# RZV2L register map
Vendor: Renesas; Series: All Chips; File version: x.xx
Registers are 32-bit, access not given, no defined reset value unless marked. A register's access mark holds for its fields unless they carry their own. Offsets are from the block's base; [hi:lo] are bit positions; {n}, {i} and the like mark numbered series.

## GPIO
Base 0x41030010
0x00 P10 8-bit
  [1:0] P10
0x01 P11 8-bit
  [1:0] P11
0x02 P12 8-bit
  [1:0] P12
0x03 P13 8-bit
  [1:0] P13
0x04 P14 8-bit
  [1:0] P14
0x05 P15 8-bit
  [2:0] P15
0x06 P16 8-bit
  [1:0] P16
0x07 P17 8-bit
  [2:0] P17
0x08 P18 8-bit
  [2:0] P18
0x09 P19 8-bit
  [1:0] P19
0x0A P1A 8-bit
  [1:0] P1A
0x0B P1B 8-bit
  [1:0] P1B
0x0C P1C 8-bit
  [1:0] P1C
0x0D P1D 8-bit
  [2:0] P1D
0x0E P1E 8-bit
  [1:0] P1E
0x0F P1F 8-bit
  [1:0] P1F
0x10 P20 8-bit
  [1:0] P20
0x11 P21 8-bit
  [2:0] P21
0x12 P22 8-bit
  [1:0] P22
0x13 P23 8-bit
  [1:0] P23
0x14 P24 8-bit
  [2:0] P24
0x15 P25 8-bit
  [1:0] P25
0x16 P26 8-bit
  [1:0] P26
0x17 P27 8-bit
  [1:0] P27
0x18 P28 8-bit
  [1:0] P28
0x19 P29 8-bit
  [1:0] P29
0x1A P2A 8-bit
  [1:0] P2A
0x1B P2B 8-bit
  [1:0] P2B
0x1C P2C 8-bit
  [1:0] P2C
0x1D P2D 8-bit
  [1:0] P2D
0x1E P2E 8-bit
  [1:0] P2E
0x1F P2F 8-bit
  [1:0] P2F
{0x2+i} P{i} 8-bit (i=30..34)
  [1:0] P{i}
0x25 P35 8-bit
  [2:0] P35
0x26 P36 8-bit
  [1:0] P36
0x27 P37 8-bit
  [2:0] P37
0x28 P38 8-bit
  [2:0] P38
0x29 P39 8-bit
  [1:0] P39
0x2A P3A 8-bit
  [4:0] P3A
0x2B P3B 8-bit
  [3:0] P3B
0x2C P3C 8-bit
  [3:0] P3C
0x2D P3D 8-bit
  [3:0] P3D
0x2E P3E 8-bit
  [3:0] P3E
0x2F P3F 8-bit
  [3:0] P3F
0x30 P40 8-bit
  [4:0] P40
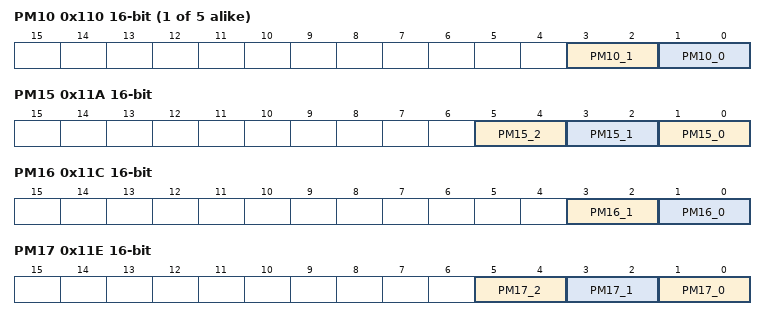
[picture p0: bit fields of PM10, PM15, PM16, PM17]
{0xFC+2i} PM{i} 16-bit (i=10..14)
  [3:2] PM{i}_1, [1:0] PM{i}_0
0x11A PM15 16-bit
  [5:4] PM15_2, [3:2] PM15_1, [1:0] PM15_0
0x11C PM16 16-bit
  [3:2] PM16_1, [1:0] PM16_0
0x11E PM17 16-bit
  [5:4] PM17_2, [3:2] PM17_1, [1:0] PM17_0
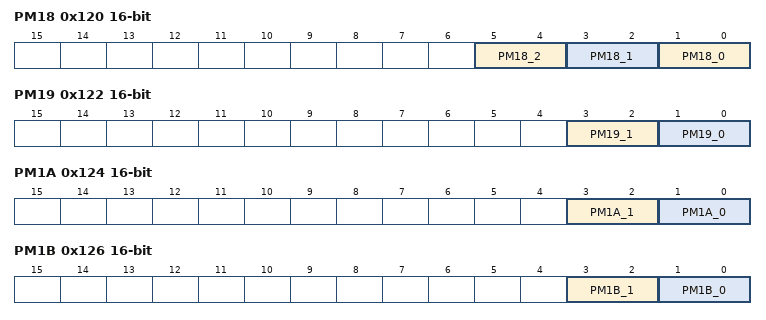
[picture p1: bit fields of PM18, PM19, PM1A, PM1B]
0x120 PM18 16-bit
  [5:4] PM18_2, [3:2] PM18_1, [1:0] PM18_0
0x122 PM19 16-bit
  [3:2] PM19_1, [1:0] PM19_0
0x124 PM1A 16-bit
  [3:2] PM1A_1, [1:0] PM1A_0
0x126 PM1B 16-bit
  [3:2] PM1B_1, [1:0] PM1B_0
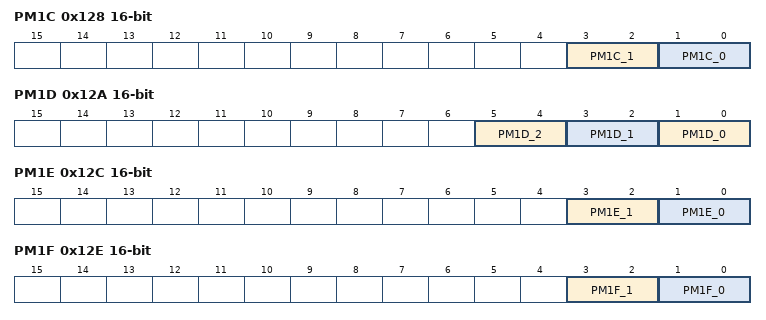
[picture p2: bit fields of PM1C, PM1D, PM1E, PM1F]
0x128 PM1C 16-bit
  [3:2] PM1C_1, [1:0] PM1C_0
0x12A PM1D 16-bit
  [5:4] PM1D_2, [3:2] PM1D_1, [1:0] PM1D_0
0x12C PM1E 16-bit
  [3:2] PM1E_1, [1:0] PM1E_0
0x12E PM1F 16-bit
  [3:2] PM1F_1, [1:0] PM1F_0
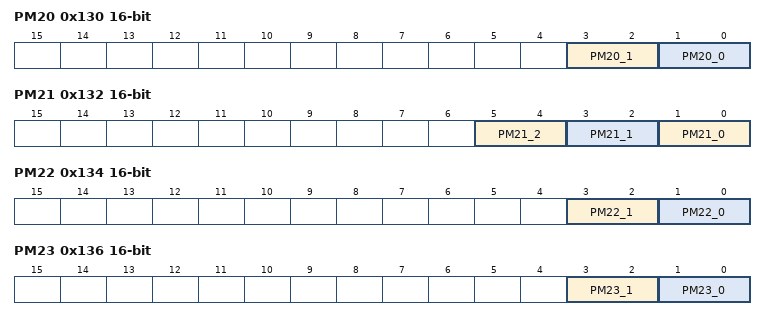
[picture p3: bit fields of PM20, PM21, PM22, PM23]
0x130 PM20 16-bit
  [3:2] PM20_1, [1:0] PM20_0
0x132 PM21 16-bit
  [5:4] PM21_2, [3:2] PM21_1, [1:0] PM21_0
0x134 PM22 16-bit
  [3:2] PM22_1, [1:0] PM22_0
0x136 PM23 16-bit
  [3:2] PM23_1, [1:0] PM23_0
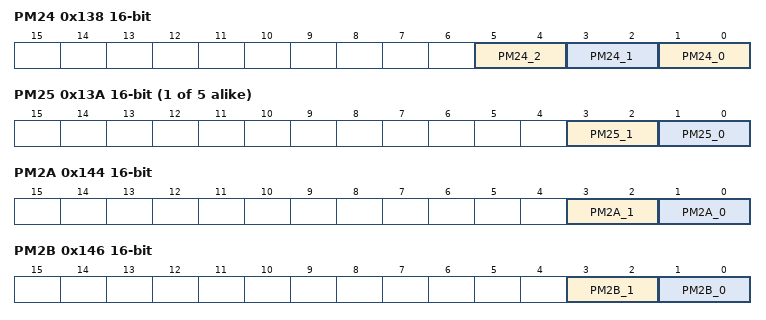
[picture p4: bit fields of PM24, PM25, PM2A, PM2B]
0x138 PM24 16-bit
  [5:4] PM24_2, [3:2] PM24_1, [1:0] PM24_0
{0x108+2i} PM{i} 16-bit (i=25..29)
  [3:2] PM{i}_1, [1:0] PM{i}_0
0x144 PM2A 16-bit
  [3:2] PM2A_1, [1:0] PM2A_0
0x146 PM2B 16-bit
  [3:2] PM2B_1, [1:0] PM2B_0
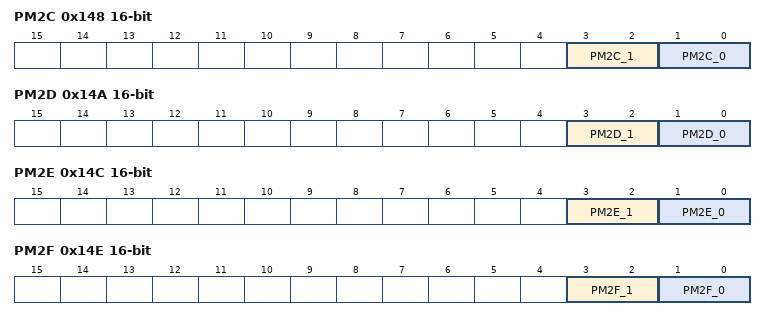
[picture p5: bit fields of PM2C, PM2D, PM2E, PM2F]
0x148 PM2C 16-bit
  [3:2] PM2C_1, [1:0] PM2C_0
0x14A PM2D 16-bit
  [3:2] PM2D_1, [1:0] PM2D_0
0x14C PM2E 16-bit
  [3:2] PM2E_1, [1:0] PM2E_0
0x14E PM2F 16-bit
  [3:2] PM2F_1, [1:0] PM2F_0
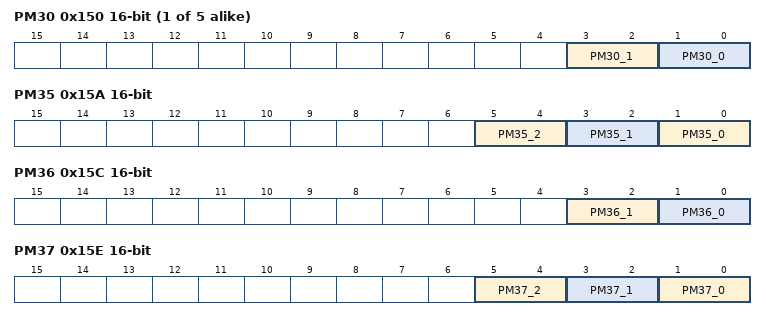
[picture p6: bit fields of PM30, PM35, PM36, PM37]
{0x114+2i} PM{i} 16-bit (i=30..34)
  [3:2] PM{i}_1, [1:0] PM{i}_0
0x15A PM35 16-bit
  [5:4] PM35_2, [3:2] PM35_1, [1:0] PM35_0
0x15C PM36 16-bit
  [3:2] PM36_1, [1:0] PM36_0
0x15E PM37 16-bit
  [5:4] PM37_2, [3:2] PM37_1, [1:0] PM37_0
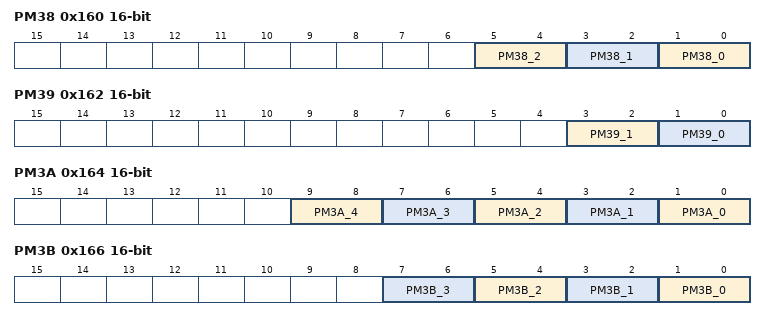
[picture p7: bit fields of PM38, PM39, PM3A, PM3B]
0x160 PM38 16-bit
  [5:4] PM38_2, [3:2] PM38_1, [1:0] PM38_0
0x162 PM39 16-bit
  [3:2] PM39_1, [1:0] PM39_0
0x164 PM3A 16-bit
  [2n+1:2n] PM3A_{n} (n=0..4)
0x166 PM3B 16-bit
  [2n+1:2n] PM3B_{n} (n=0..3)
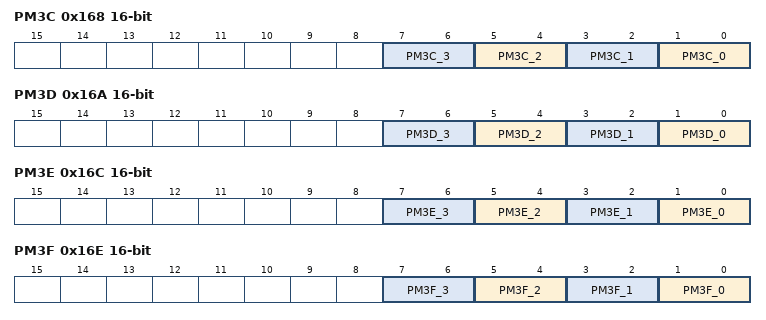
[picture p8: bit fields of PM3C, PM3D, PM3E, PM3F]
0x168 PM3C 16-bit
  [2n+1:2n] PM3C_{n} (n=0..3)
0x16A PM3D 16-bit
  [2n+1:2n] PM3D_{n} (n=0..3)
0x16C PM3E 16-bit
  [2n+1:2n] PM3E_{n} (n=0..3)
0x16E PM3F 16-bit
  [2n+1:2n] PM3F_{n} (n=0..3)
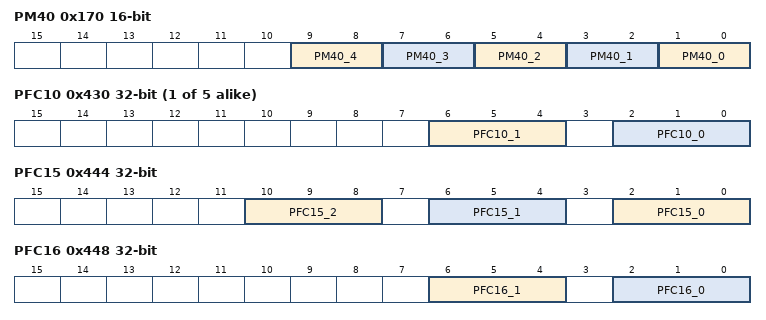
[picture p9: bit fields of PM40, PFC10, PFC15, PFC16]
0x170 PM40 16-bit
  [2n+1:2n] PM40_{n} (n=0..4)
{0x1F6+i} PMC{i} 8-bit (i=10..14)
  [1:0] PMC{i}
0x205 PMC15 8-bit
  [2:0] PMC15
0x206 PMC16 8-bit
  [1:0] PMC16
0x207 PMC17 8-bit
  [2:0] PMC17
0x208 PMC18 8-bit
  [2:0] PMC18
0x209 PMC19 8-bit
  [1:0] PMC19
0x20A PMC1A 8-bit
  [1:0] PMC1A
0x20B PMC1B 8-bit
  [1:0] PMC1B
0x20C PMC1C 8-bit
  [1:0] PMC1C
0x20D PMC1D 8-bit
  [2:0] PMC1D
0x20E PMC1E 8-bit
  [1:0] PMC1E
0x20F PMC1F 8-bit
  [1:0] PMC1F
0x210 PMC20 8-bit
  [1:0] PMC20
0x211 PMC21 8-bit
  [2:0] PMC21
0x212 PMC22 8-bit
  [1:0] PMC22
0x213 PMC23 8-bit
  [1:0] PMC23
0x214 PMC24 8-bit
  [2:0] PMC24
{0x1FC+i} PMC{i} 8-bit (i=25..29)
  [1:0] PMC{i}
0x21A PMC2A 8-bit
  [1:0] PMC2A
0x21B PMC2B 8-bit
  [1:0] PMC2B
0x21C PMC2C 8-bit
  [1:0] PMC2C
0x21D PMC2D 8-bit
  [1:0] PMC2D
0x21E PMC2E 8-bit
  [1:0] PMC2E
0x21F PMC2F 8-bit
  [1:0] PMC2F
{0x202+i} PMC{i} 8-bit (i=30..34)
  [1:0] PMC{i}
0x225 PMC35 8-bit
  [2:0] PMC35
0x226 PMC36 8-bit
  [1:0] PMC36
0x227 PMC37 8-bit
  [2:0] PMC37
0x228 PMC38 8-bit
  [2:0] PMC38
0x229 PMC39 8-bit
  [1:0] PMC39
0x22A PMC3A 8-bit
  [4:0] PMC3A
0x22B PMC3B 8-bit
  [3:0] PMC3B
0x22C PMC3C 8-bit
  [3:0] PMC3C
0x22D PMC3D 8-bit
  [3:0] PMC3D
0x22E PMC3E 8-bit
  [3:0] PMC3E
0x22F PMC3F 8-bit
  [3:0] PMC3F
0x230 PMC40 8-bit
  [4:0] PMC40
{0x408+4i} PFC{i} (i=10..14)
  [6:4] PFC{i}_1, [2:0] PFC{i}_0
0x444 PFC15
  [10:8] PFC15_2, [6:4] PFC15_1, [2:0] PFC15_0
0x448 PFC16
  [6:4] PFC16_1, [2:0] PFC16_0
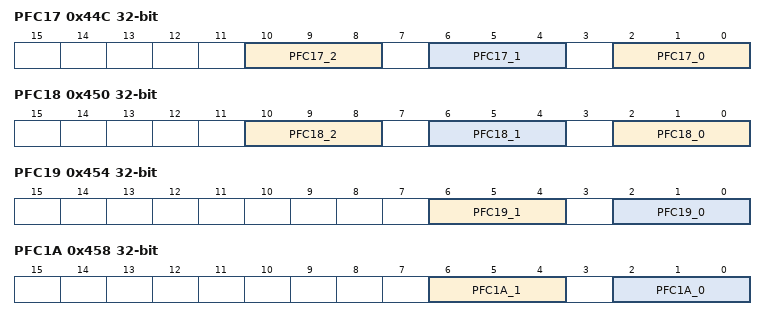
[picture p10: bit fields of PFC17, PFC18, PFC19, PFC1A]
0x44C PFC17
  [10:8] PFC17_2, [6:4] PFC17_1, [2:0] PFC17_0
0x450 PFC18
  [10:8] PFC18_2, [6:4] PFC18_1, [2:0] PFC18_0
0x454 PFC19
  [6:4] PFC19_1, [2:0] PFC19_0
0x458 PFC1A
  [6:4] PFC1A_1, [2:0] PFC1A_0
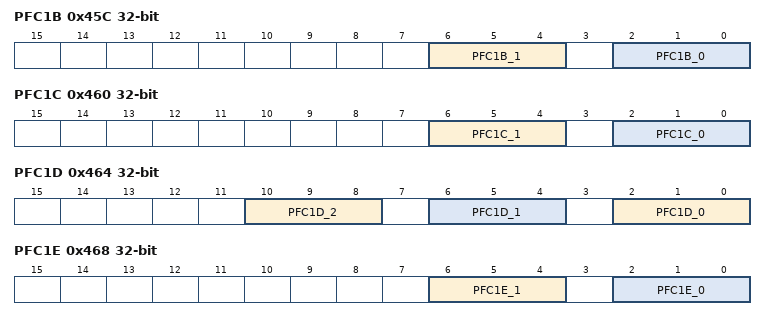
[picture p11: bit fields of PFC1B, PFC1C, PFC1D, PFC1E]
0x45C PFC1B
  [6:4] PFC1B_1, [2:0] PFC1B_0
0x460 PFC1C
  [6:4] PFC1C_1, [2:0] PFC1C_0
0x464 PFC1D
  [10:8] PFC1D_2, [6:4] PFC1D_1, [2:0] PFC1D_0
0x468 PFC1E
  [6:4] PFC1E_1, [2:0] PFC1E_0
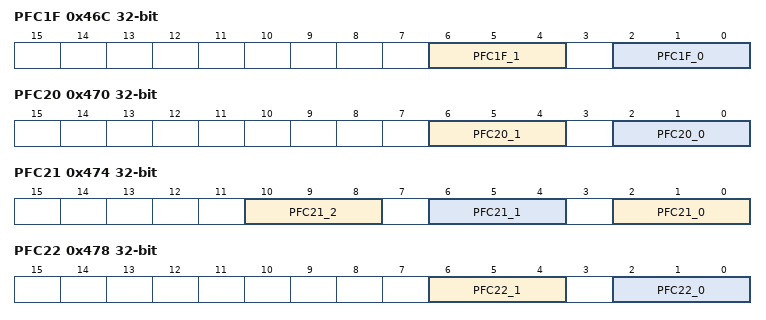
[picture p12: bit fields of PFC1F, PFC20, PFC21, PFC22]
0x46C PFC1F
  [6:4] PFC1F_1, [2:0] PFC1F_0
0x470 PFC20
  [6:4] PFC20_1, [2:0] PFC20_0
0x474 PFC21
  [10:8] PFC21_2, [6:4] PFC21_1, [2:0] PFC21_0
0x478 PFC22
  [6:4] PFC22_1, [2:0] PFC22_0
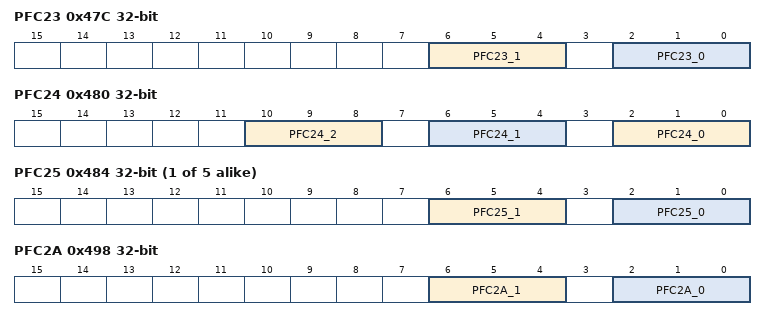
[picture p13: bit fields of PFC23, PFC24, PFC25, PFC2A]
0x47C PFC23
  [6:4] PFC23_1, [2:0] PFC23_0
0x480 PFC24
  [10:8] PFC24_2, [6:4] PFC24_1, [2:0] PFC24_0
{0x420+4i} PFC{i} (i=25..29)
  [6:4] PFC{i}_1, [2:0] PFC{i}_0
0x498 PFC2A
  [6:4] PFC2A_1, [2:0] PFC2A_0
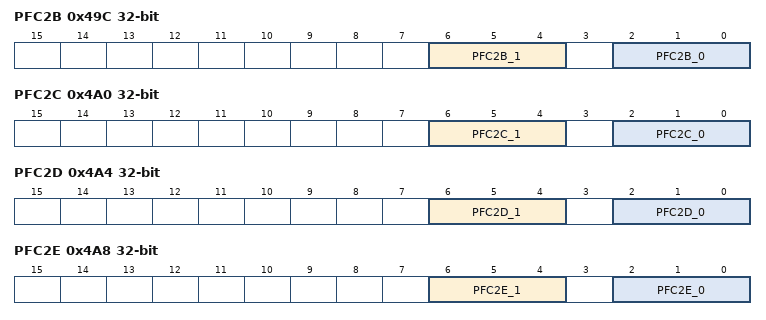
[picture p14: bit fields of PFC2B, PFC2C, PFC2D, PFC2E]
0x49C PFC2B
  [6:4] PFC2B_1, [2:0] PFC2B_0
0x4A0 PFC2C
  [6:4] PFC2C_1, [2:0] PFC2C_0
0x4A4 PFC2D
  [6:4] PFC2D_1, [2:0] PFC2D_0
0x4A8 PFC2E
  [6:4] PFC2E_1, [2:0] PFC2E_0
0x4AC PFC2F
  [6:4] PFC2F_1, [2:0] PFC2F_0
{0x438+4i} PFC{i} (i=30..34)
  [6:4] PFC{i}_1, [2:0] PFC{i}_0
0x4C4 PFC35
  [10:8] PFC35_2, [6:4] PFC35_1, [2:0] PFC35_0
0x4C8 PFC36
  [6:4] PFC36_1, [2:0] PFC36_0
0x4CC PFC37
  [10:8] PFC37_2, [6:4] PFC37_1, [2:0] PFC37_0
0x4D0 PFC38
  [10:8] PFC38_2, [6:4] PFC38_1, [2:0] PFC38_0
0x4D4 PFC39
  [6:4] PFC39_1, [2:0] PFC39_0
0x4D8 PFC3A
  [4n+2:4n] PFC3A_{n} (n=0..4)
0x4DC PFC3B
  [4n+2:4n] PFC3B_{n} (n=0..3)
0x4E0 PFC3C
  [4n+2:4n] PFC3C_{n} (n=0..3)
0x4E4 PFC3D
  [4n+2:4n] PFC3D_{n} (n=0..3)
0x4E8 PFC3E
  [4n+2:4n] PFC3E_{n} (n=0..3)
0x4EC PFC3F
  [4n+2:4n] PFC3F_{n} (n=0..3)
0x4F0 PFC40
  [4n+2:4n] PFC40_{n} (n=0..4)
{0x7F6+i} PIN{i} 8-bit (i=10..14)
  [1:0] PIN{i}
0x805 PIN15 8-bit
  [2:0] PIN15
0x806 PIN16 8-bit
  [1:0] PIN16
0x807 PIN17 8-bit
  [2:0] PIN17
0x808 PIN18 8-bit
  [2:0] PIN18
0x809 PIN19 8-bit
  [1:0] PIN19
0x80A PIN1A 8-bit
  [1:0] PIN1A
0x80B PIN1B 8-bit
  [1:0] PIN1B
0x80C PIN1C 8-bit
  [1:0] PIN1C
0x80D PIN1D 8-bit
  [2:0] PIN1D
0x80E PIN1E 8-bit
  [1:0] PIN1E
0x80F PIN1F 8-bit
  [1:0] PIN1F
0x810 PIN20 8-bit
  [1:0] PIN20
0x811 PIN21 8-bit
  [2:0] PIN21
0x812 PIN22 8-bit
  [1:0] PIN22
0x813 PIN23 8-bit
  [1:0] PIN23
0x814 PIN24 8-bit
  [2:0] PIN24
{0x7FC+i} PIN{i} 8-bit (i=25..29)
  [1:0] PIN{i}
0x81A PIN2A 8-bit
  [1:0] PIN2A
0x81B PIN2B 8-bit
  [1:0] PIN2B
0x81C PIN2C 8-bit
  [1:0] PIN2C
0x81D PIN2D 8-bit
  [1:0] PIN2D
0x81E PIN2E 8-bit
  [1:0] PIN2E
0x81F PIN2F 8-bit
  [1:0] PIN2F
{0x802+i} PIN{i} 8-bit (i=30..34)
  [1:0] PIN{i}
0x825 PIN35 8-bit
  [2:0] PIN35
0x826 PIN36 8-bit
  [1:0] PIN36
0x827 PIN37 8-bit
  [2:0] PIN37
0x828 PIN38 8-bit
  [2:0] PIN38
0x829 PIN39 8-bit
  [1:0] PIN39
0x82A PIN3A 8-bit
  [4:0] PIN3A
0x82B PIN3B 8-bit
  [3:0] PIN3B
0x82C PIN3C 8-bit
  [3:0] PIN3C
0x82D PIN3D 8-bit
  [3:0] PIN3D
0x82E PIN3E 8-bit
  [3:0] PIN3E
0x82F PIN3F 8-bit
  [3:0] PIN3F
0x830 PIN40 8-bit
  [4:0] PIN40
0x1000 IOLH02
  [1:0] IOLH02_0
0x1008 IOLH03
  [1:0] IOLH03_0
0x1020 IOLH06
  [17:16] IOLH06_2, [9:8] IOLH06_1, [1:0] IOLH06_0
0x1028 IOLH07_L
  [8n+1:8n] IOLH07_L_{n} (n=0..3)
0x102C IOLH07_H
  [8n+1:8n] IOLH07_H_{n} (n=0..3)
0x1030 IOLH08
  [9:8] IOLH08_1, [1:0] IOLH08_0
0x1038 IOLH09
  [8n+1:8n] IOLH09_{n} (n=0..3)
0x1040 IOLH0A_L
  [8n+1:8n] IOLH0A_L_{n} (n=0..3)
0x1044 IOLH0A_H
  [9:8] IOLH0A_H_1, [1:0] IOLH0A_H_0
0x1048 IOLH0B_L
  [8n+1:8n] IOLH0B_L_{n} (n=0..3)
0x104C IOLH0B_H
  [9:8] IOLH0B_H_1, [1:0] IOLH0B_H_0
0x1050 IOLH0C
  [9:8] IOLH0C_1, [1:0] IOLH0C_0
0x1058 IOLH0D
  [1:0] IOLH0D_0
{0x1020+8i} IOLH{i} (i=10..14)
  [9:8] IOLH{i}_1, [1:0] IOLH{i}_0
0x1098 IOLH15
  [17:16] IOLH15_2, [9:8] IOLH15_1, [1:0] IOLH15_0
0x10A0 IOLH16
  [9:8] IOLH16_1, [1:0] IOLH16_0
0x10A8 IOLH17
  [17:16] IOLH17_2, [9:8] IOLH17_1, [1:0] IOLH17_0
0x10B0 IOLH18
  [17:16] IOLH18_2, [9:8] IOLH18_1, [1:0] IOLH18_0
0x10B8 IOLH19
  [9:8] IOLH19_1, [1:0] IOLH19_0
0x10C0 IOLH1A
  [9:8] IOLH1A_1, [1:0] IOLH1A_0
0x10C8 IOLH1B
  [9:8] IOLH1B_1, [1:0] IOLH1B_0
0x10D0 IOLH1C
  [9:8] IOLH1C_1, [1:0] IOLH1C_0
0x10D8 IOLH1D
  [17:16] IOLH1D_2, [9:8] IOLH1D_1, [1:0] IOLH1D_0
0x10E0 IOLH1E
  [9:8] IOLH1E_1, [1:0] IOLH1E_0
0x10E8 IOLH1F
  [9:8] IOLH1F_1, [1:0] IOLH1F_0
0x10F0 IOLH20
  [9:8] IOLH20_1, [1:0] IOLH20_0
0x10F8 IOLH21
  [17:16] IOLH21_2, [9:8] IOLH21_1, [1:0] IOLH21_0
0x1100 IOLH22
  [9:8] IOLH22_1, [1:0] IOLH22_0
0x1108 IOLH23
  [9:8] IOLH23_1, [1:0] IOLH23_0
0x11A0 IOLH36
  [9:8] IOLH36_1, [1:0] IOLH36_0
0x11A8 IOLH37
  [17:16] IOLH37_2, [9:8] IOLH37_1, [1:0] IOLH37_0
0x11B0 IOLH38
  [17:16] IOLH38_2, [9:8] IOLH38_1, [1:0] IOLH38_0
0x11B8 IOLH39
  [9:8] IOLH39_1, [1:0] IOLH39_0
0x11C0 IOLH3A_L
  [8n+1:8n] IOLH3A_L_{n} (n=0..3)
0x11C4 IOLH3A_H
  [1:0] IOLH3A_H_0
0x11C8 IOLH3B
  [8n+1:8n] IOLH3B_{n} (n=0..3)
0x11D0 IOLH3C
  [8n+1:8n] IOLH3C_{n} (n=0..3)
0x11D8 IOLH3D
  [8n+1:8n] IOLH3D_{n} (n=0..3)
0x11E0 IOLH3E
  [8n+1:8n] IOLH3E_{n} (n=0..3)
0x11E8 IOLH3F
  [8n+1:8n] IOLH3F_{n} (n=0..3)
0x11F0 IOLH40_L
  [8n+1:8n] IOLH40_L_{n} (n=0..3)
0x11F4 IOLH40_H
  [1:0] IOLH40_H_0
0x1400 SR02
  [0] SR02_0
0x1408 SR03
  [0] SR03_0
0x1420 SR06
  [16] SR06_2, [8] SR06_1, [0] SR06_0
0x1428 SR07_L
  [8n] SR07_L_{n} (n=0..3)
0x142C SR07_H
  [8n] SR07_H_{n} (n=0..3)
0x1430 SR08
  [8] SR08_1, [0] SR08_0
0x1438 SR09
  [8n] SR09_{n} (n=0..3)
0x1440 SR0A_L
  [8n] SR0A_L_{n} (n=0..3)
0x1444 SR0A_H
  [8] SR0A_H_1, [0] SR0A_H_0
0x1448 SR0B_L
  [8n] SR0B_L_{n} (n=0..3)
0x144C SR0B_H
  [8] SR0B_H_1, [0] SR0B_H_0
0x1450 SR0C
  [16] SR0C_2, [8] SR0C_1, [0] SR0C_0
0x1458 SR0D
  [0] SR0D_0
{0x1420+8i} SR{i} (i=10..14)
  [8] SR{i}_1, [0] SR{i}_0
0x1498 SR15
  [16] SR15_2, [8] SR15_1, [0] SR15_0
0x14A0 SR16
  [8] SR16_1, [0] SR16_0
0x14A8 SR17
  [16] SR17_2, [8] SR17_1, [0] SR17_0
0x14B0 SR18
  [16] SR18_2, [8] SR18_1, [0] SR18_0
0x14B8 SR19
  [8] SR19_1, [0] SR19_0
0x14C0 SR1A
  [8] SR1A_1, [0] SR1A_0
0x14C8 SR1B
  [8] SR1B_1, [0] SR1B_0
0x14D0 SR1C
  [8] SR1C_1, [0] SR1C_0
0x14D8 SR1D
  [16] SR1D_2, [8] SR1D_1, [0] SR1D_0
0x14E0 SR1E
  [8] SR1E_1, [0] SR1E_0
0x14E8 SR1F
  [8] SR1F_1, [0] SR1F_0
0x14F0 SR20
  [8] SR20_1, [0] SR20_0
0x14F8 SR21
  [16] SR21_2, [8] SR21_1, [0] SR21_0
0x1500 SR22
  [8] SR22_1, [0] SR22_0
0x1508 SR23
  [8] SR23_1, [0] SR23_0
0x15A0 SR36
  [8] SR36_1, [0] SR36_0
0x15A8 SR37
  [16] SR37_2, [8] SR37_1, [0] SR37_0
0x15B0 SR38
  [16] SR38_2, [8] SR38_1, [0] SR38_0
0x15B8 SR39
  [8] SR39_1, [0] SR39_0
0x15C0 SR3A_L
  [8n] SR3A_L_{n} (n=0..3)
0x15C4 SR3A_H
  [0] SR3A_H_0
0x15C8 SR3B
  [8n] SR3B_{n} (n=0..3)
0x15D0 SR3C
  [8n] SR3C_{n} (n=0..3)
0x15D8 SR3D
  [8n] SR3D_{n} (n=0..3)
0x15E0 SR3E
  [8n] SR3E_{n} (n=0..3)
0x15E8 SR3F
  [8n] SR3F_{n} (n=0..3)
0x15F0 SR40_L
  [8n] SR40_L_{n} (n=0..3)
0x15F4 SR40_H
  [0] SR40_H_0
0x1800 IEN02
  [0] IEN02_0
0x1810 IEN04
  [8] IEN04_1, [0] IEN04_0
0x1820 IEN06
  [8] IEN06_1
0x1828 IEN07_L
  [8n] IEN07_L_{n} (n=0..3)
0x182C IEN07_H
  [8n] IEN07_H_{n} (n=0..3)
0x1830 IEN08
  [8] IEN08_1
0x1838 IEN09
  [8n] IEN09_{n} (n=0..3)
0x1860 IEN0E
  [8n] IEN0E_{n} (n=0..3)
{0x1C20+8i} PUPD{i} (i=10..14)
  [9:8] PUPD{i}_1, [1:0] PUPD{i}_0
0x1C98 PUPD15
  [17:16] PUPD15_2, [9:8] PUPD15_1, [1:0] PUPD15_0
0x1CA0 PUPD16
  [9:8] PUPD16_1, [1:0] PUPD16_0
0x1CA8 PUPD17
  [17:16] PUPD17_2, [9:8] PUPD17_1, [1:0] PUPD17_0
0x1CB0 PUPD18
  [17:16] PUPD18_2, [9:8] PUPD18_1, [1:0] PUPD18_0
0x1CB8 PUPD19
  [9:8] PUPD19_1, [1:0] PUPD19_0
0x1CC0 PUPD1A
  [9:8] PUPD1A_1, [1:0] PUPD1A_0
0x1CC8 PUPD1B
  [9:8] PUPD1B_1, [1:0] PUPD1B_0
0x1CD0 PUPD1C
  [9:8] PUPD1C_1, [1:0] PUPD1C_0
0x1CD8 PUPD1D
  [17:16] PUPD1D_2, [9:8] PUPD1D_1, [1:0] PUPD1D_0
0x1CE0 PUPD1E
  [9:8] PUPD1E_1, [1:0] PUPD1E_0
0x1CE8 PUPD1F
  [9:8] PUPD1F_1, [1:0] PUPD1F_0
0x1CF0 PUPD20
  [9:8] PUPD20_1, [1:0] PUPD20_0
0x1CF8 PUPD21
  [17:16] PUPD21_2, [9:8] PUPD21_1, [1:0] PUPD21_0
0x1D00 PUPD22
  [9:8] PUPD22_1, [1:0] PUPD22_0
0x1D08 PUPD23
  [9:8] PUPD23_1, [1:0] PUPD23_0
0x1DA0 PUPD36
  [9:8] PUPD36_1, [1:0] PUPD36_0
0x1DA8 PUPD37
  [17:16] PUPD37_2, [9:8] PUPD37_1, [1:0] PUPD37_0
0x1DB0 PUPD38
  [17:16] PUPD38_2, [9:8] PUPD38_1, [1:0] PUPD38_0
0x1DB8 PUPD39
  [9:8] PUPD39_1, [1:0] PUPD39_0
0x1DC0 PUPD3A_L
  [8n+1:8n] PUPD3A_L_{n} (n=0..3)
0x1DC4 PUPD3A_H
  [1:0] PUPD3A_H_0
0x1DC8 PUPD3B
  [8n+1:8n] PUPD3B_{n} (n=0..3)
0x1DD0 PUPD3C
  [8n+1:8n] PUPD3C_{n} (n=0..3)
0x1DD8 PUPD3D
  [8n+1:8n] PUPD3D_{n} (n=0..3)
0x1DE0 PUPD3E
  [8n+1:8n] PUPD3E_{n} (n=0..3)
0x1DE8 PUPD3F
  [8n+1:8n] PUPD3F_{n} (n=0..3)
0x1DF0 PUPD40_L
  [8n+1:8n] PUPD40_L_{n} (n=0..3)
0x1DF4 PUPD40_H
  [1:0] PUPD40_H_0
0x1FF8 FILONOFF01
  [0] FILONOFF01_0
{0x2020+8i} FILONOFF{i} (i=10..14)
  [8] FILONOFF{i}_1, [0] FILONOFF{i}_0
0x2098 FILONOFF15
  [16] FILONOFF15_2, [8] FILONOFF15_1, [0] FILONOFF15_0
0x20A0 FILONOFF16
  [8] FILONOFF16_1, [0] FILONOFF16_0
0x20A8 FILONOFF17
  [16] FILONOFF17_2, [8] FILONOFF17_1, [0] FILONOFF17_0
0x20B0 FILONOFF18
  [16] FILONOFF18_2, [8] FILONOFF18_1, [0] FILONOFF18_0
0x20B8 FILONOFF19
  [8] FILONOFF19_1, [0] FILONOFF19_0
0x20C0 FILONOFF1A
  [8] FILONOFF1A_1, [0] FILONOFF1A_0
0x20C8 FILONOFF1B
  [8] FILONOFF1B_1, [0] FILONOFF1B_0
0x20D0 FILONOFF1C
  [8] FILONOFF1C_1, [0] FILONOFF1C_0
0x20D8 FILONOFF1D
  [16] FILONOFF1D_2, [8] FILONOFF1D_1, [0] FILONOFF1D_0
0x20E0 FILONOFF1E
  [8] FILONOFF1E_1, [0] FILONOFF1E_0
0x20E8 FILONOFF1F
  [8] FILONOFF1F_1, [0] FILONOFF1F_0
0x20F0 FILONOFF20
  [8] FILONOFF20_1, [0] FILONOFF20_0
0x20F8 FILONOFF21
  [16] FILONOFF21_2, [8] FILONOFF21_1, [0] FILONOFF21_0
0x2100 FILONOFF22
  [8] FILONOFF22_1, [0] FILONOFF22_0
0x2108 FILONOFF23
  [8] FILONOFF23_1, [0] FILONOFF23_0
0x2110 FILONOFF24
  [16] FILONOFF24_2, [8] FILONOFF24_1, [0] FILONOFF24_0
{0x2050+8i} FILONOFF{i} (i=25..29)
  [8] FILONOFF{i}_1, [0] FILONOFF{i}_0
0x2140 FILONOFF2A
  [8] FILONOFF2A_1, [0] FILONOFF2A_0
0x2148 FILONOFF2B
  [8] FILONOFF2B_1, [0] FILONOFF2B_0
0x2150 FILONOFF2C
  [8] FILONOFF2C_1, [0] FILONOFF2C_0
0x2158 FILONOFF2D
  [8] FILONOFF2D_1, [0] FILONOFF2D_0
0x2160 FILONOFF2E
  [8] FILONOFF2E_1, [0] FILONOFF2E_0
0x2168 FILONOFF2F
  [8] FILONOFF2F_1, [0] FILONOFF2F_0
{0x2080+8i} FILONOFF{i} (i=30..34)
  [8] FILONOFF{i}_1, [0] FILONOFF{i}_0
0x2198 FILONOFF35
  [16] FILONOFF35_2, [8] FILONOFF35_1, [0] FILONOFF35_0
0x21A0 FILONOFF36
  [8] FILONOFF36_1, [0] FILONOFF36_0
0x21A8 FILONOFF37
  [16] FILONOFF37_2, [8] FILONOFF37_1, [0] FILONOFF37_0
0x21B0 FILONOFF38
  [16] FILONOFF38_2, [8] FILONOFF38_1, [0] FILONOFF38_0
0x21B8 FILONOFF39
  [8] FILONOFF39_1, [0] FILONOFF39_0
0x21C0 FILONOFF3A_L
  [8n] FILONOFF3A_L_{n} (n=0..3)
0x21C4 FILONOFF3A_H
  [0] FILONOFF3A_H_0
0x21C8 FILONOFF3B
  [8n] FILONOFF3B_{n} (n=0..3)
0x21D0 FILONOFF3C
  [8n] FILONOFF3C_{n} (n=0..3)
0x21D8 FILONOFF3D
  [8n] FILONOFF3D_{n} (n=0..3)
0x21E0 FILONOFF3E
  [8n] FILONOFF3E_{n} (n=0..3)
0x21E8 FILONOFF3F
  [8n] FILONOFF3F_{n} (n=0..3)
0x21F0 FILONOFF40_L
  [8n] FILONOFF40_L_{n} (n=0..3)
0x21F4 FILONOFF40_H
  [0] FILONOFF40_H_0
0x23F8 FILNUM01
  [1:0] FILNUM01_0
{0x2420+8i} FILNUM{i} (i=10..14)
  [9:8] FILNUM{i}_1, [1:0] FILNUM{i}_0
0x2498 FILNUM15
  [17:16] FILNUM15_2, [9:8] FILNUM15_1, [1:0] FILNUM15_0
0x24A0 FILNUM16
  [9:8] FILNUM16_1, [1:0] FILNUM16_0
0x24A8 FILNUM17
  [17:16] FILNUM17_2, [9:8] FILNUM17_1, [1:0] FILNUM17_0
0x24B0 FILNUM18
  [17:16] FILNUM18_2, [9:8] FILNUM18_1, [1:0] FILNUM18_0
0x24B8 FILNUM19
  [9:8] FILNUM19_1, [1:0] FILNUM19_0
0x24C0 FILNUM1A
  [9:8] FILNUM1A_1, [1:0] FILNUM1A_0
0x24C8 FILNUM1B
  [9:8] FILNUM1B_1, [1:0] FILNUM1B_0
0x24D0 FILNUM1C
  [9:8] FILNUM1C_1, [1:0] FILNUM1C_0
0x24D8 FILNUM1D
  [17:16] FILNUM1D_2, [9:8] FILNUM1D_1, [1:0] FILNUM1D_0
0x24E0 FILNUM1E
  [9:8] FILNUM1E_1, [1:0] FILNUM1E_0
0x24E8 FILNUM1F
  [9:8] FILNUM1F_1, [1:0] FILNUM1F_0
0x24F0 FILNUM20
  [9:8] FILNUM20_1, [1:0] FILNUM20_0
0x24F8 FILNUM21
  [17:16] FILNUM21_2, [9:8] FILNUM21_1, [1:0] FILNUM21_0
0x2500 FILNUM22
  [9:8] FILNUM22_1, [1:0] FILNUM22_0
0x2508 FILNUM23
  [9:8] FILNUM23_1, [1:0] FILNUM23_0
0x2510 FILNUM24
  [17:16] FILNUM24_2, [9:8] FILNUM24_1, [1:0] FILNUM24_0
{0x2450+8i} FILNUM{i} (i=25..29)
  [9:8] FILNUM{i}_1, [1:0] FILNUM{i}_0
0x2540 FILNUM2A
  [9:8] FILNUM2A_1, [1:0] FILNUM2A_0
0x2548 FILNUM2B
  [9:8] FILNUM2B_1, [1:0] FILNUM2B_0
0x2550 FILNUM2C
  [9:8] FILNUM2C_1, [1:0] FILNUM2C_0
0x2558 FILNUM2D
  [9:8] FILNUM2D_1, [1:0] FILNUM2D_0
0x2560 FILNUM2E
  [9:8] FILNUM2E_1, [1:0] FILNUM2E_0
0x2568 FILNUM2F
  [9:8] FILNUM2F_1, [1:0] FILNUM2F_0
{0x2480+8i} FILNUM{i} (i=30..34)
  [9:8] FILNUM{i}_1, [1:0] FILNUM{i}_0
0x2598 FILNUM35
  [17:16] FILNUM35_2, [9:8] FILNUM35_1, [1:0] FILNUM35_0
0x25A0 FILNUM36
  [9:8] FILNUM36_1, [1:0] FILNUM36_0
0x25A8 FILNUM37
  [17:16] FILNUM37_2, [9:8] FILNUM37_1, [1:0] FILNUM37_0
0x25B0 FILNUM38
  [17:16] FILNUM38_2, [9:8] FILNUM38_1, [1:0] FILNUM38_0
0x25B8 FILNUM39
  [9:8] FILNUM39_1, [1:0] FILNUM39_0
0x25C0 FILNUM3A_L
  [8n+1:8n] FILNUM3A_L_{n} (n=0..3)
0x25C4 FILNUM3A_H
  [1:0] FILNUM3A_H_0
0x25C8 FILNUM3B
  [8n+1:8n] FILNUM3B_{n} (n=0..3)
0x25D0 FILNUM3C
  [8n+1:8n] FILNUM3C_{n} (n=0..3)
0x25D8 FILNUM3D
  [8n+1:8n] FILNUM3D_{n} (n=0..3)
0x25E0 FILNUM3E
  [8n+1:8n] FILNUM3E_{n} (n=0..3)
0x25E8 FILNUM3F
  [8n+1:8n] FILNUM3F_{n} (n=0..3)
0x25F0 FILNUM40_L
  [8n+1:8n] FILNUM40_L_{n} (n=0..3)
0x25F4 FILNUM40_H
  [1:0] FILNUM40_H_0
0x27F8 FILCLKSEL01
  [1:0] FILCLKSEL01_0
{0x2820+8i} FILCLKSEL{i} (i=10..14)
  [9:8] FILCLKSEL{i}_1, [1:0] FILCLKSEL{i}_0
0x2898 FILCLKSEL15
  [17:16] FILCLKSEL15_2, [9:8] FILCLKSEL15_1, [1:0] FILCLKSEL15_0
0x28A0 FILCLKSEL16
  [9:8] FILCLKSEL16_1, [1:0] FILCLKSEL16_0
0x28A8 FILCLKSEL17
  [17:16] FILCLKSEL17_2, [9:8] FILCLKSEL17_1, [1:0] FILCLKSEL17_0
0x28B0 FILCLKSEL18
  [17:16] FILCLKSEL18_2, [9:8] FILCLKSEL18_1, [1:0] FILCLKSEL18_0
0x28B8 FILCLKSEL19
  [9:8] FILCLKSEL19_1, [1:0] FILCLKSEL19_0
0x28C0 FILCLKSEL1A
  [9:8] FILCLKSEL1A_1, [1:0] FILCLKSEL1A_0
0x28C8 FILCLKSEL1B
  [9:8] FILCLKSEL1B_1, [1:0] FILCLKSEL1B_0
0x28D0 FILCLKSEL1C
  [9:8] FILCLKSEL1C_1, [1:0] FILCLKSEL1C_0
0x28D8 FILCLKSEL1D
  [17:16] FILCLKSEL1D_2, [9:8] FILCLKSEL1D_1, [1:0] FILCLKSEL1D_0
0x28E0 FILCLKSEL1E
  [9:8] FILCLKSEL1E_1, [1:0] FILCLKSEL1E_0
0x28E8 FILCLKSEL1F
  [9:8] FILCLKSEL1F_1, [1:0] FILCLKSEL1F_0
0x28F0 FILCLKSEL20
  [9:8] FILCLKSEL20_1, [1:0] FILCLKSEL20_0
0x28F8 FILCLKSEL21
  [17:16] FILCLKSEL21_2, [9:8] FILCLKSEL21_1, [1:0] FILCLKSEL21_0
0x2900 FILCLKSEL22
  [9:8] FILCLKSEL22_1, [1:0] FILCLKSEL22_0
0x2908 FILCLKSEL23
  [9:8] FILCLKSEL23_1, [1:0] FILCLKSEL23_0
0x2910 FILCLKSEL24
  [17:16] FILCLKSEL24_2, [9:8] FILCLKSEL24_1, [1:0] FILCLKSEL24_0
{0x2850+8i} FILCLKSEL{i} (i=25..29)
  [9:8] FILCLKSEL{i}_1, [1:0] FILCLKSEL{i}_0
0x2940 FILCLKSEL2A
  [9:8] FILCLKSEL2A_1, [1:0] FILCLKSEL2A_0
0x2948 FILCLKSEL2B
  [9:8] FILCLKSEL2B_1, [1:0] FILCLKSEL2B_0
0x2950 FILCLKSEL2C
  [9:8] FILCLKSEL2C_1, [1:0] FILCLKSEL2C_0
0x2958 FILCLKSEL2D
  [9:8] FILCLKSEL2D_1, [1:0] FILCLKSEL2D_0
0x2960 FILCLKSEL2E
  [9:8] FILCLKSEL2E_1, [1:0] FILCLKSEL2E_0
0x2968 FILCLKSEL2F
  [9:8] FILCLKSEL2F_1, [1:0] FILCLKSEL2F_0
{0x2880+8i} FILCLKSEL{i} (i=30..34)
  [9:8] FILCLKSEL{i}_1, [1:0] FILCLKSEL{i}_0
0x2998 FILCLKSEL35
  [17:16] FILCLKSEL35_2, [9:8] FILCLKSEL35_1, [1:0] FILCLKSEL35_0
0x29A0 FILCLKSEL36
  [9:8] FILCLKSEL36_1, [1:0] FILCLKSEL36_0
0x29A8 FILCLKSEL37
  [17:16] FILCLKSEL37_2, [9:8] FILCLKSEL37_1, [1:0] FILCLKSEL37_0
0x29B0 FILCLKSEL38
  [17:16] FILCLKSEL38_2, [9:8] FILCLKSEL38_1, [1:0] FILCLKSEL38_0
0x29B8 FILCLKSEL39
  [9:8] FILCLKSEL39_1, [1:0] FILCLKSEL39_0
0x29C0 FILCLKSEL3A_L
  [8n+1:8n] FILCLKSEL3A_L_{n} (n=0..3)
0x29C4 FILCLKSEL3A_H
  [1:0] FILCLKSEL3A_H_0
0x29C8 FILCLKSEL3B
  [8n+1:8n] FILCLKSEL3B_{n} (n=0..3)
0x29D0 FILCLKSEL3C
  [8n+1:8n] FILCLKSEL3C_{n} (n=0..3)
0x29D8 FILCLKSEL3D
  [8n+1:8n] FILCLKSEL3D_{n} (n=0..3)
0x29E0 FILCLKSEL3E
  [8n+1:8n] FILCLKSEL3E_{n} (n=0..3)
0x29E8 FILCLKSEL3F
  [8n+1:8n] FILCLKSEL3F_{n} (n=0..3)
0x29F0 FILCLKSEL40_L
  [8n+1:8n] FILCLKSEL40_L_{n} (n=0..3)
0x29F4 FILCLKSEL40_H
  [1:0] FILCLKSEL40_H_0
{0x2C20+8i} ISEL{i} (i=10..14)
  [8] ISEL{i}_1, [0] ISEL{i}_0
0x2C98 ISEL15
  [16] ISEL15_2, [8] ISEL15_1, [0] ISEL15_0
0x2CA0 ISEL16
  [8] ISEL16_1, [0] ISEL16_0
0x2CA8 ISEL17
  [16] ISEL17_2, [8] ISEL17_1, [0] ISEL17_0
0x2CB0 ISEL18
  [16] ISEL18_2, [8] ISEL18_1, [0] ISEL18_0
0x2CB8 ISEL19
  [8] ISEL19_1, [0] ISEL19_0
0x2CC0 ISEL1A
  [8] ISEL1A_1, [0] ISEL1A_0
0x2CC8 ISEL1B
  [8] ISEL1B_1, [0] ISEL1B_0
0x2CD0 ISEL1C
  [8] ISEL1C_1, [0] ISEL1C_0
0x2CD8 ISEL1D
  [16] ISEL1D_2, [8] ISEL1D_1, [0] ISEL1D_0
0x2CE0 ISEL1E
  [8] ISEL1E_1, [0] ISEL1E_0
0x2CE8 ISEL1F
  [8] ISEL1F_1, [0] ISEL1F_0
0x2CF0 ISEL20
  [8] ISEL20_1, [0] ISEL20_0
0x2CF8 ISEL21
  [16] ISEL21_2, [8] ISEL21_1, [0] ISEL21_0
0x2D00 ISEL22
  [8] ISEL22_1, [0] ISEL22_0
0x2D08 ISEL23
  [8] ISEL23_1, [0] ISEL23_0
0x2D10 ISEL24
  [16] ISEL24_2, [8] ISEL24_1, [0] ISEL24_0
{0x2C50+8i} ISEL{i} (i=25..29)
  [8] ISEL{i}_1, [0] ISEL{i}_0
0x2D40 ISEL2A
  [8] ISEL2A_1, [0] ISEL2A_0
0x2D48 ISEL2B
  [8] ISEL2B_1, [0] ISEL2B_0
0x2D50 ISEL2C
  [8] ISEL2C_1, [0] ISEL2C_0
0x2D58 ISEL2D
  [8] ISEL2D_1, [0] ISEL2D_0
0x2D60 ISEL2E
  [8] ISEL2E_1, [0] ISEL2E_0
0x2D68 ISEL2F
  [8] ISEL2F_1, [0] ISEL2F_0
{0x2C80+8i} ISEL{i} (i=30..34)
  [8] ISEL{i}_1, [0] ISEL{i}_0
0x2D98 ISEL35
  [16] ISEL35_2, [8] ISEL35_1, [0] ISEL35_0
0x2DA0 ISEL36
  [8] ISEL36_1, [0] ISEL36_0
0x2DA8 ISEL37
  [16] ISEL37_2, [8] ISEL37_1, [0] ISEL37_0
0x2DB0 ISEL38
  [16] ISEL38_2, [8] ISEL38_1, [0] ISEL38_0
0x2DB8 ISEL39
  [8] ISEL39_1, [0] ISEL39_0
0x2DC0 ISEL3A_L
  [8n] ISEL3A_L_{n} (n=0..3)
0x2DC4 ISEL3A_H
  [0] ISEL3A_H_0
0x2DC8 ISEL3B
  [8n] ISEL3B_{n} (n=0..3)
0x2DD0 ISEL3C
  [8n] ISEL3C_{n} (n=0..3)
0x2DD8 ISEL3D
  [8n] ISEL3D_{n} (n=0..3)
0x2DE0 ISEL3E
  [8n] ISEL3E_{n} (n=0..3)
0x2DE8 ISEL3F
  [8n] ISEL3F_{n} (n=0..3)
0x2DF0 ISEL40_L
  [8n] ISEL40_L_{n} (n=0..3)
0x2DF4 ISEL40_H
  [0] ISEL40_H_0
0x2FF0 SD_ch0 8-bit
  [0] SD0_PVDD
0x2FF4 SD_ch1 8-bit
  [0] SD1_PVDD
0x2FF8 QSPI 8-bit
  [0] QSPI_PVDD
0x2FFC ETH_ch0 8-bit
  [1] ETH0_25V_PVDD, [0] ETH0_18V_PVDD
0x3000 ETH_ch1 8-bit
  [1] ETH1_25V_PVDD, [0] ETH1_18V_PVDD
0x3004 PWPR 8-bit
  [7] BOWI, [6] PFCWE
0x3008 ETH_MII_RGMII 8-bit
  [1] P29_0, [0] P20_0
